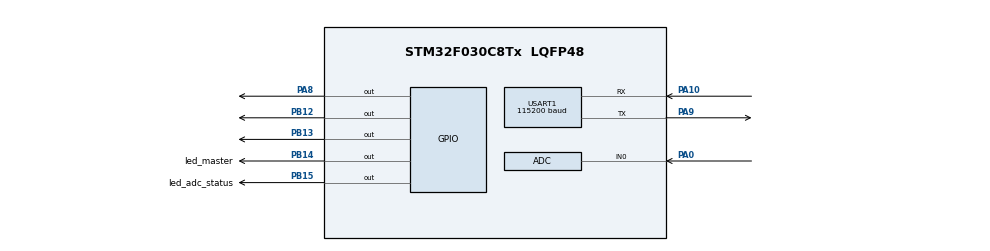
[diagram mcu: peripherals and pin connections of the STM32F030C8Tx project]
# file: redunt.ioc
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Dma.ADC.0.Direction=DMA_PERIPH_TO_MEMORY
Dma.ADC.0.Instance=DMA1_Channel1
Dma.ADC.0.MemDataAlignment=DMA_MDATAALIGN_HALFWORD
Dma.ADC.0.MemInc=DMA_MINC_ENABLE
Dma.ADC.0.Mode=DMA_NORMAL
Dma.ADC.0.PeriphDataAlignment=DMA_PDATAALIGN_HALFWORD
Dma.ADC.0.PeriphInc=DMA_PINC_DISABLE
Dma.ADC.0.Priority=DMA_PRIORITY_LOW
Dma.Request0=ADC
Mcu.Family=STM32F0
Mcu.Name=STM32F030C8Tx
Mcu.Package=LQFP48
NVIC.ADC1_IRQn=true\:0\:0\:false\:false\:true\:true
NVIC.DMA1_Channel1_IRQn=true\:0\:0\:false\:false\:true\:false
PA0.Mode=IN0
PA0.Signal=ADC_IN0
PA10.Mode=Asynchronous
PA10.Signal=USART1_RX
PA8.Signal=GPIO_Output
PA9.Mode=Asynchronous
PA9.Signal=USART1_TX
PB12.Signal=GPIO_Output
PB13.Signal=GPIO_Output
PB14.GPIO_Label=led_master
PB14.Signal=GPIO_Output
PB15.GPIO_Label=led_adc_status
PB15.Signal=GPIO_Output
ProjectManager.HeapSize=0x200
ProjectManager.StackSize=0x400
ProjectManager.TargetToolchain=MDK-ARM V5
USART1.BaudRate=115200
USART1.VirtualMode-Asynchronous=VM_ASYNC
board=custom

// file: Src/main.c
/* USER CODE BEGIN Header */
/**
  ******************************************************************************
  * @file           : main.c
  * @brief          : Main program body
  ******************************************************************************
  ** This notice applies to any and all portions of this file
  * that are not between comment pairs USER CODE BEGIN and
  * USER CODE END. Other portions of this file, whether
  * inserted by the user or by software development tools
  * are owned by their respective copyright owners.
  *
  * COPYRIGHT(c) 2019 STMicroelectronics
  *
  * Redistribution and use in source and binary forms, with or without modification,
  * are permitted provided that the following conditions are met:
  *   1. Redistributions of source code must retain the above copyright notice,
  *      this list of conditions and the following disclaimer.
  *   2. Redistributions in binary form must reproduce the above copyright notice,
  *      this list of conditions and the following disclaimer in the documentation
  *      and/or other materials provided with the distribution.
  *   3. Neither the name of STMicroelectronics nor the names of its contributors
  *      may be used to endorse or promote products derived from this software
  *      without specific prior written permission.
  *
  * THIS SOFTWARE IS PROVIDED BY THE COPYRIGHT HOLDERS AND CONTRIBUTORS "AS IS"
  * AND ANY EXPRESS OR IMPLIED WARRANTIES, INCLUDING, BUT NOT LIMITED TO, THE
  * IMPLIED WARRANTIES OF MERCHANTABILITY AND FITNESS FOR A PARTICULAR PURPOSE ARE
  * DISCLAIMED. IN NO EVENT SHALL THE COPYRIGHT HOLDER OR CONTRIBUTORS BE LIABLE
  * FOR ANY DIRECT, INDIRECT, INCIDENTAL, SPECIAL, EXEMPLARY, OR CONSEQUENTIAL
  * DAMAGES (INCLUDING, BUT NOT LIMITED TO, PROCUREMENT OF SUBSTITUTE GOODS OR
  * SERVICES; LOSS OF USE, DATA, OR PROFITS; OR BUSINESS INTERRUPTION) HOWEVER
  * CAUSED AND ON ANY THEORY OF LIABILITY, WHETHER IN CONTRACT, STRICT LIABILITY,
  * OR TORT (INCLUDING NEGLIGENCE OR OTHERWISE) ARISING IN ANY WAY OUT OF THE USE
  * OF THIS SOFTWARE, EVEN IF ADVISED OF THE POSSIBILITY OF SUCH DAMAGE.
  *
  ******************************************************************************
  */
/* USER CODE END Header */

#include "main.h"

/* USER CODE BEGIN Includes */
#include "adc.h"
/* USER CODE END Includes */

ADC_HandleTypeDef hadc;
DMA_HandleTypeDef hdma_adc;

UART_HandleTypeDef huart1;

void SystemClock_Config(void);
static void MX_GPIO_Init(void);
static void MX_DMA_Init(void);
static void MX_USART1_UART_Init(void);
static void MX_ADC_Init(void);
/* USER CODE BEGIN PFP */
uint32_t adc_dma_value;
/* USER CODE END PFP */

int main(void)
{

  /* MCU Configuration--------------------------------------------------------*/

  /* Reset of all peripherals, Initializes the Flash interface and the Systick. */
  HAL_Init();

  /* Configure the system clock */
  SystemClock_Config();

  /* Initialize all configured peripherals */
  MX_GPIO_Init();
  MX_DMA_Init();
  MX_USART1_UART_Init();
  MX_ADC_Init();
  /* USER CODE BEGIN 2 */
   HAL_ADC_Start_DMA(&hadc, &adc_dma_value,1);
  /* USER CODE END 2 */

  /* Infinite loop */
  while (1)
  {

    /* USER CODE BEGIN 3 */
	adc_process();
  }
  /* USER CODE END 3 */
}

void SystemClock_Config(void)
{
  RCC_OscInitTypeDef RCC_OscInitStruct = {0};
  RCC_ClkInitTypeDef RCC_ClkInitStruct = {0};
  RCC_PeriphCLKInitTypeDef PeriphClkInit = {0};

  /**Initializes the CPU, AHB and APB busses clocks
  */
  RCC_OscInitStruct.OscillatorType = RCC_OSCILLATORTYPE_HSI|RCC_OSCILLATORTYPE_HSI14;
  RCC_OscInitStruct.HSIState = RCC_HSI_ON;
  RCC_OscInitStruct.HSI14State = RCC_HSI14_ON;
  RCC_OscInitStruct.HSICalibrationValue = RCC_HSICALIBRATION_DEFAULT;
  RCC_OscInitStruct.HSI14CalibrationValue = 16;
  RCC_OscInitStruct.PLL.PLLState = RCC_PLL_NONE;
  if (HAL_RCC_OscConfig(&RCC_OscInitStruct) != HAL_OK)
  {
    Error_Handler();
  }
  /**Initializes the CPU, AHB and APB busses clocks
  */
  RCC_ClkInitStruct.ClockType = RCC_CLOCKTYPE_HCLK|RCC_CLOCKTYPE_SYSCLK
                              |RCC_CLOCKTYPE_PCLK1;
  RCC_ClkInitStruct.SYSCLKSource = RCC_SYSCLKSOURCE_HSI;
  RCC_ClkInitStruct.AHBCLKDivider = RCC_SYSCLK_DIV1;
  RCC_ClkInitStruct.APB1CLKDivider = RCC_HCLK_DIV1;

  if (HAL_RCC_ClockConfig(&RCC_ClkInitStruct, FLASH_LATENCY_0) != HAL_OK)
  {
    Error_Handler();
  }
  PeriphClkInit.PeriphClockSelection = RCC_PERIPHCLK_USART1;
  PeriphClkInit.Usart1ClockSelection = RCC_USART1CLKSOURCE_PCLK1;
  if (HAL_RCCEx_PeriphCLKConfig(&PeriphClkInit) != HAL_OK)
  {
    Error_Handler();
  }
}

static void MX_ADC_Init(void)
{

  ADC_ChannelConfTypeDef sConfig = {0};

  /**Configure the global features of the ADC (Clock, Resolution, Data Alignment and number of conversion)
  */
  hadc.Instance = ADC1;
  hadc.Init.ClockPrescaler = ADC_CLOCK_ASYNC_DIV1;
  hadc.Init.Resolution = ADC_RESOLUTION_12B;
  hadc.Init.DataAlign = ADC_DATAALIGN_RIGHT;
  hadc.Init.ScanConvMode = ADC_SCAN_DIRECTION_FORWARD;
  hadc.Init.EOCSelection = ADC_EOC_SINGLE_CONV;
  hadc.Init.LowPowerAutoWait = DISABLE;
  hadc.Init.LowPowerAutoPowerOff = DISABLE;
  hadc.Init.ContinuousConvMode = DISABLE;
  hadc.Init.DiscontinuousConvMode = DISABLE;
  hadc.Init.ExternalTrigConv = ADC_SOFTWARE_START;
  hadc.Init.ExternalTrigConvEdge = ADC_EXTERNALTRIGCONVEDGE_NONE;
  hadc.Init.DMAContinuousRequests = DISABLE;
  hadc.Init.Overrun = ADC_OVR_DATA_PRESERVED;
  if (HAL_ADC_Init(&hadc) != HAL_OK)
  {
    Error_Handler();
  }
  /**Configure for the selected ADC regular channel to be converted.
  */
  sConfig.Channel = ADC_CHANNEL_0;
  sConfig.Rank = ADC_RANK_CHANNEL_NUMBER;
  sConfig.SamplingTime = ADC_SAMPLETIME_1CYCLE_5;
  if (HAL_ADC_ConfigChannel(&hadc, &sConfig) != HAL_OK)
  {
    Error_Handler();
  }

}

static void MX_USART1_UART_Init(void)
{

  huart1.Instance = USART1;
  huart1.Init.BaudRate = 115200;
  huart1.Init.WordLength = UART_WORDLENGTH_8B;
  huart1.Init.StopBits = UART_STOPBITS_1;
  huart1.Init.Parity = UART_PARITY_NONE;
  huart1.Init.Mode = UART_MODE_TX_RX;
  huart1.Init.HwFlowCtl = UART_HWCONTROL_NONE;
  huart1.Init.OverSampling = UART_OVERSAMPLING_16;
  huart1.Init.OneBitSampling = UART_ONE_BIT_SAMPLE_DISABLE;
  huart1.AdvancedInit.AdvFeatureInit = UART_ADVFEATURE_NO_INIT;
  if (HAL_UART_Init(&huart1) != HAL_OK)
  {
    Error_Handler();
  }

}

static void MX_DMA_Init(void)
{
  /* DMA controller clock enable */
  __HAL_RCC_DMA1_CLK_ENABLE();

  /* DMA interrupt init */
  /* DMA1_Channel1_IRQn interrupt configuration */
  HAL_NVIC_SetPriority(DMA1_Channel1_IRQn, 0, 0);
  HAL_NVIC_EnableIRQ(DMA1_Channel1_IRQn);

}

static void MX_GPIO_Init(void)
{
  GPIO_InitTypeDef GPIO_InitStruct = {0};

  /* GPIO Ports Clock Enable */
  __HAL_RCC_GPIOA_CLK_ENABLE();
  __HAL_RCC_GPIOB_CLK_ENABLE();

  /*Configure GPIO pin Output Level */
  HAL_GPIO_WritePin(GPIOB, GPIO_PIN_12|GPIO_PIN_13|led_master_Pin|led_adc_status_Pin, GPIO_PIN_RESET);

  /*Configure GPIO pin Output Level */
  HAL_GPIO_WritePin(GPIOA, GPIO_PIN_8, GPIO_PIN_RESET);

  /*Configure GPIO pins : PB12 PB13 led_master_Pin led_adc_status_Pin */
  GPIO_InitStruct.Pin = GPIO_PIN_12|GPIO_PIN_13|led_master_Pin|led_adc_status_Pin;
  GPIO_InitStruct.Mode = GPIO_MODE_OUTPUT_PP;
  GPIO_InitStruct.Pull = GPIO_NOPULL;
  GPIO_InitStruct.Speed = GPIO_SPEED_FREQ_LOW;
  HAL_GPIO_Init(GPIOB, &GPIO_InitStruct);

  /*Configure GPIO pin : PA8 */
  GPIO_InitStruct.Pin = GPIO_PIN_8;
  GPIO_InitStruct.Mode = GPIO_MODE_OUTPUT_PP;
  GPIO_InitStruct.Pull = GPIO_NOPULL;
  GPIO_InitStruct.Speed = GPIO_SPEED_FREQ_LOW;
  HAL_GPIO_Init(GPIOA, &GPIO_InitStruct);

}

void Error_Handler(void)
{
}

/************************ (C) COPYRIGHT STMicroelectronics *****END OF FILE****/
